AUTOSAR XML (schema 4-2-2)
package /ASW_COM_Package
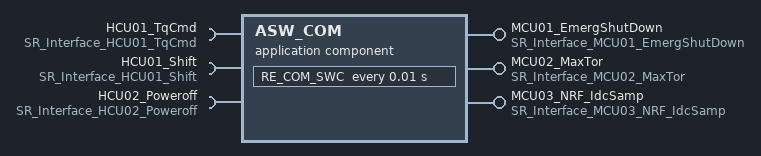
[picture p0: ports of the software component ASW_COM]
  application sw component type ASW_COM
    provide port MCU01_EmergShutDown: provided-interface=SR_Interface_MCU01_EmergShutDown
    provide port MCU02_MaxTor: provided-interface=SR_Interface_MCU02_MaxTor
    provide port MCU03_NRF_IdcSamp: provided-interface=SR_Interface_MCU03_NRF_IdcSamp
    require port HCU01_TqCmd: required-interface=SR_Interface_HCU01_TqCmd
    require port HCU01_Shift: required-interface=SR_Interface_HCU01_Shift
    require port HCU02_Poweroff: nonqueued-receiver-com-spec{data-element=DE_HCU02_Poweroff, alive-timeout=0.3}, required-interface=SR_Interface_HCU02_Poweroff
    behavior IB_ASW_COM
      timing event TE_RE_COM_SWC_10ms: start-on-event=RE_COM_SWC, period=0.01
      runnable RE_COM_SWC
        data-read-accesses:
          access VA_READ_HCU01_TqCmd: accessed-variable=HCU01_TqCmd.DE_HCU01_TqCmd
          access VA_READ_HCU01_Shift: accessed-variable=HCU01_Shift.DE_HCU01_Shift
          access VA_READ_HCU02_Poweroff: accessed-variable=HCU02_Poweroff.DE_HCU02_Poweroff
        data-write-accesses:
          access VA_WRITE_MCU01_EmergShutDown: accessed-variable=MCU01_EmergShutDown.DE_MCU01_EmergShutDown
          access VA_WRITE_MCU02_MaxTor: accessed-variable=MCU02_MaxTor.DE_MCU02_MaxTor
          access VA_WRITE_MCU03_NRF_IdcSamp: accessed-variable=MCU03_NRF_IdcSamp.DE_MCU03_NRF_IdcSamp
